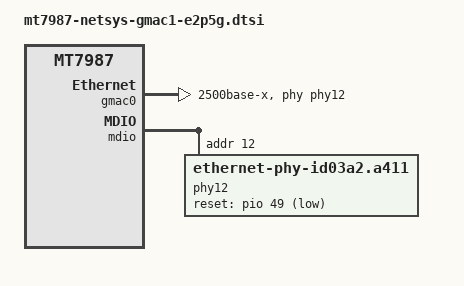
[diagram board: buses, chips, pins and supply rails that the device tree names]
// SPDX-License-Identifier: (GPL-2.0 OR MIT)

&gmac0 {
	mac-type = "gdm";
	phy-mode = "2500base-x";
	phy-handle = <&phy12>;

	/delete-node/ fixed-link;
};

&mdio {
	/delete-node/ switch@1;
	phy12: phy@12 {
		compatible = "ethernet-phy-id03a2.a411";
		reg = <12>;
		reset-gpios = <&pio 49 1>;
		reset-assert-us = <10000>;
		reset-deassert-us = <10000>;
		phy-mode = "2500base-x";
		full-duplex;
		pause;
		airoha,polarity = <1>;
		airoha,surge = <0>;
		airoha,phy-handle;
	};
};

&hnat {
	mtketh-lan = "eth0";
};
